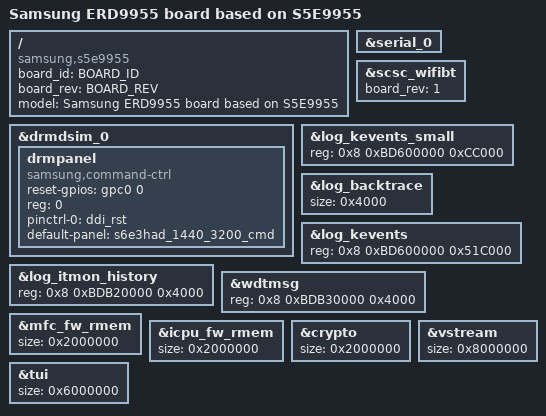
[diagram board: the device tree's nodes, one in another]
/*
 * SAMSUNG S5E9955 board device tree source
 *
 * Copyright (c) 2023 Samsung Electronics Co., Ltd.
 *		http://www.samsung.com
 *
 * This program is free software; you can redistribute it and/or modify
 * it under the terms of the GNU General Public License version 2 as
 * published by the Free Software Foundation.
 */

/dts-v1/;
/plugin/;

#include "s5e9955-erd9955_common.dtsi"
#include <dt-bindings/gpio/gpio.h>
#include "panel/samsung-s6e3had-1440-3200-command-panel.dtsi"

#define BOARD_ID	0x0
#define BOARD_REV	0x2

/ {
	compatible = "samsung,s5e9955", "samsung,ERD9955";
	board_id = <BOARD_ID>;
	board_rev = <BOARD_REV>;

	fragment@model {
		target-path = "/";
		__overlay__ {
			#address-cells = <2>;
			#size-cells = <1>;

			model = "Samsung ERD9955 board based on S5E9955";
		}; /* end of __overlay__ */
	}; /* end of fragment */
}; /* end of root */

&serial_0 {
	status = "okay";
};

&drmdsim_0 {
	#address-cells = <1>;
	#size-cells = <0>;
	drmpanel {
		compatible = "samsung,command-ctrl";
		/* reset, power */
		reset-gpios = <&gpc0 0 GPIO_ACTIVE_HIGH>;
		reg = <0>;
		pinctrl-names = "default";
		pinctrl-0 = <&ddi_rst>;

		default-panel = "s6e3had_1440_3200_cmd";
	};
};

&scsc_wifibt {
	board_rev = <1>;
};

&log_kevents_small {
	reg = <0x8 0xBD600000 0xCC000>;
};

&log_backtrace {
	size = <0x4000>;
};

&log_kevents {
	reg = <0x8 0xBD600000 0x51C000>;
};

&log_itmon_history {
	reg = <0x8 0xBDB20000 0x4000>;
};

&wdtmsg {
	reg = <0x8 0xBDB30000 0x4000>;
};

&mfc_fw_rmem {
	size = <0x2000000>;
};

&icpu_fw_rmem {
	size = <0x2000000>;
};

&crypto {
	size = <0x2000000>;
};

&vstream {
	size = <0x8000000>;
};

&tui {
	size = <0x6000000>;
};
